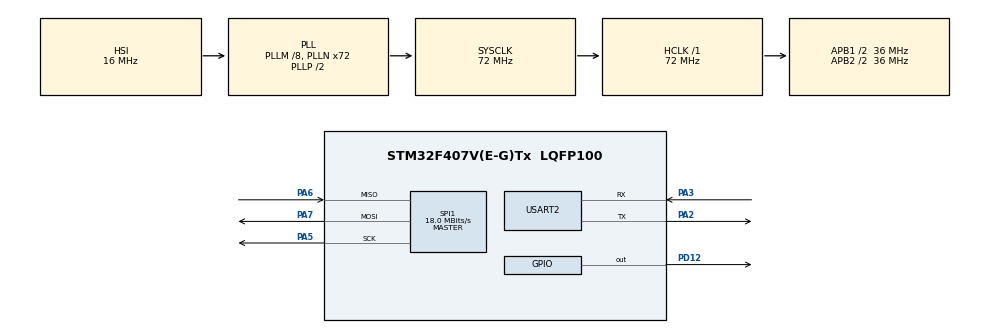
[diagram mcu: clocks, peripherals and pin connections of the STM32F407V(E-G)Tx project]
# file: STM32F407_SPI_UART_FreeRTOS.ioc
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FREERTOS.Tasks01=defaultTask,0,128,StartDefaultTask,Default,NULL
Mcu.Family=STM32F4
Mcu.Name=STM32F407V(E-G)Tx
Mcu.Package=LQFP100
NVIC.PriorityGroup=NVIC_PRIORITYGROUP_4
NVIC.TIM1_UP_TIM10_IRQn=true\:0\:0\:false\:false\:true\:false\:false
NVIC.TimeBase=TIM1_UP_TIM10_IRQn
NVIC.TimeBaseIP=TIM1
PA2.Mode=Asynchronous
PA2.Signal=USART2_TX
PA3.Mode=Asynchronous
PA3.Signal=USART2_RX
PA5.Mode=Full_Duplex_Master
PA5.Signal=SPI1_SCK
PA6.Mode=Full_Duplex_Master
PA6.Signal=SPI1_MISO
PA7.Mode=Full_Duplex_Master
PA7.Signal=SPI1_MOSI
PD12.Signal=GPIO_Output
PH0-OSC_IN.Mode=HSE-External-Oscillator
PH0-OSC_IN.Signal=RCC_OSC_IN
PH1-OSC_OUT.Mode=HSE-External-Oscillator
PH1-OSC_OUT.Signal=RCC_OSC_OUT
ProjectManager.HeapSize=0x200
ProjectManager.StackSize=0x400
ProjectManager.TargetToolchain=TrueSTUDIO
RCC.48MHZClocksFreq_Value=36000000
RCC.AHBFreq_Value=72000000
RCC.APB1CLKDivider=RCC_HCLK_DIV2
RCC.APB1Freq_Value=36000000
RCC.APB1TimFreq_Value=72000000
RCC.APB2CLKDivider=RCC_HCLK_DIV2
RCC.APB2Freq_Value=36000000
RCC.APB2TimFreq_Value=72000000
RCC.CortexFreq_Value=72000000
RCC.HCLKFreq_Value=72000000
RCC.HSE_VALUE=8000000
RCC.HSI_VALUE=16000000
RCC.LSE_VALUE=32768
RCC.PLLM=8
RCC.PLLN=72
RCC.SYSCLKFreq_VALUE=72000000
RCC.SYSCLKSource=RCC_SYSCLKSOURCE_PLLCLK
RCC.VCOOutputFreq_Value=144000000
SPI1.BaudRatePrescaler=SPI_BAUDRATEPRESCALER_2
SPI1.CalculateBaudRate=18.0 MBits/s
SPI1.Direction=SPI_DIRECTION_2LINES
SPI1.Mode=SPI_MODE_MASTER
SPI1.VirtualType=VM_MASTER
USART2.VirtualMode=VM_ASYNC
VP_FREERTOS_VS_ENABLE.Mode=Enabled
VP_SYS_VS_tim1.Mode=TIM1
board=STM32F407_SPI_UART_FreeRTOS

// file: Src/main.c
/**
  ******************************************************************************
  * File Name          : main.c
  * Description        : Main program body
  ******************************************************************************
  * This notice applies to any and all portions of this file
  * that are not between comment pairs USER CODE BEGIN and
  * USER CODE END. Other portions of this file, whether
  * inserted by the user or by software development tools
  * are owned by their respective copyright owners.
  *
  * Copyright (c) 2020 STMicroelectronics International N.V.
  * All rights reserved.
  *
  * Redistribution and use in source and binary forms, with or without
  * modification, are permitted, provided that the following conditions are met:
  *
  * 1. Redistribution of source code must retain the above copyright notice,
  *    this list of conditions and the following disclaimer.
  * 2. Redistributions in binary form must reproduce the above copyright notice,
  *    this list of conditions and the following disclaimer in the documentation
  *    and/or other materials provided with the distribution.
  * 3. Neither the name of STMicroelectronics nor the names of other
  *    contributors to this software may be used to endorse or promote products
  *    derived from this software without specific written permission.
  * 4. This software, including modifications and/or derivative works of this
  *    software, must execute solely and exclusively on microcontroller or
  *    microprocessor devices manufactured by or for STMicroelectronics.
  * 5. Redistribution and use of this software other than as permitted under
  *    this license is void and will automatically terminate your rights under
  *    this license.
  *
  * THIS SOFTWARE IS PROVIDED BY STMICROELECTRONICS AND CONTRIBUTORS "AS IS"
  * AND ANY EXPRESS, IMPLIED OR STATUTORY WARRANTIES, INCLUDING, BUT NOT
  * LIMITED TO, THE IMPLIED WARRANTIES OF MERCHANTABILITY, FITNESS FOR A
  * PARTICULAR PURPOSE AND NON-INFRINGEMENT OF THIRD PARTY INTELLECTUAL PROPERTY
  * RIGHTS ARE DISCLAIMED TO THE FULLEST EXTENT PERMITTED BY LAW. IN NO EVENT
  * SHALL STMICROELECTRONICS OR CONTRIBUTORS BE LIABLE FOR ANY DIRECT, INDIRECT,
  * INCIDENTAL, SPECIAL, EXEMPLARY, OR CONSEQUENTIAL DAMAGES (INCLUDING, BUT NOT
  * LIMITED TO, PROCUREMENT OF SUBSTITUTE GOODS OR SERVICES; LOSS OF USE, DATA,
  * OR PROFITS; OR BUSINESS INTERRUPTION) HOWEVER CAUSED AND ON ANY THEORY OF
  * LIABILITY, WHETHER IN CONTRACT, STRICT LIABILITY, OR TORT (INCLUDING
  * NEGLIGENCE OR OTHERWISE) ARISING IN ANY WAY OUT OF THE USE OF THIS SOFTWARE,
  * EVEN IF ADVISED OF THE POSSIBILITY OF SUCH DAMAGE.
  *
  ******************************************************************************
  */

#include "main.h"
#include "stm32f4xx_hal.h"
#include "cmsis_os.h"

SPI_HandleTypeDef hspi1;

UART_HandleTypeDef huart2;

osThreadId defaultTaskHandle;

/* USER CODE BEGIN PV */
/* Private variables ---------------------------------------------------------*/

/* USER CODE END PV */

void SystemClock_Config(void);
static void MX_GPIO_Init(void);
static void MX_USART2_UART_Init(void);
static void MX_SPI1_Init(void);
void StartDefaultTask(void const * argument);

/* USER CODE BEGIN PFP */
/* Private function prototypes -----------------------------------------------*/

/* USER CODE END PFP */

/* USER CODE BEGIN 0 */

void UART_task1()
{
	uint8_t pData[100];
	while(1)
	{
//		HAL_UART_Receive( &huart2, pData, sizeof(pData), 500);
		vTaskDelay(1);
	}
}

void SPI_task2()
{
	uint8_t pData[100];
	while(1)
	{
		HAL_SPI_Receive( &hspi1, pData, sizeof(pData), 500);
		HAL_UART_Transmit( &huart2, pData, sizeof(pData), 500);
		memset(pData,'\0', sizeof(pData));
		vTaskDelay(1);
	}
}

/* USER CODE END 0 */

int main(void)
{

  /* MCU Configuration----------------------------------------------------------*/

  /* Reset of all peripherals, Initializes the Flash interface and the Systick. */
  HAL_Init();

  /* Configure the system clock */
  SystemClock_Config();

  /* Initialize all configured peripherals */
  MX_GPIO_Init();
  MX_USART2_UART_Init();
  MX_SPI1_Init();

  /* Create the thread(s) */
  /* definition and creation of defaultTask */
  osThreadDef(defaultTask, StartDefaultTask, osPriorityNormal, 0, 128);
  defaultTaskHandle = osThreadCreate(osThread(defaultTask), NULL);

  /* USER CODE BEGIN RTOS_THREADS */
  /* add threads, ... */

  /* Add the main task into FreeRTOS task scheduler. */
  		xTaskCreate(UART_task1, "Main Task1", 512, NULL, 1, NULL);
  		xTaskCreate(SPI_task2, "Main Task2", 512, NULL, 0, NULL);

  		/* Start FreeRTOS task scheduler. */
  		vTaskStartScheduler();

  /* USER CODE END RTOS_THREADS */

  /* Start scheduler */
  osKernelStart();

  /* We should never get here as control is now taken by the scheduler */

  /* Infinite loop */
  while (1)
  {

  }

}

/** System Clock Configuration
*/
void SystemClock_Config(void)
{

  RCC_OscInitTypeDef RCC_OscInitStruct;
  RCC_ClkInitTypeDef RCC_ClkInitStruct;

    /**Configure the main internal regulator output voltage
    */
  __HAL_RCC_PWR_CLK_ENABLE();

  __HAL_PWR_VOLTAGESCALING_CONFIG(PWR_REGULATOR_VOLTAGE_SCALE1);

    /**Initializes the CPU, AHB and APB busses clocks
    */
  RCC_OscInitStruct.OscillatorType = RCC_OSCILLATORTYPE_HSI;
  RCC_OscInitStruct.HSIState = RCC_HSI_ON;
  RCC_OscInitStruct.HSICalibrationValue = 16;
  RCC_OscInitStruct.PLL.PLLState = RCC_PLL_ON;
  RCC_OscInitStruct.PLL.PLLSource = RCC_PLLSOURCE_HSI;
  RCC_OscInitStruct.PLL.PLLM = 8;
  RCC_OscInitStruct.PLL.PLLN = 72;
  RCC_OscInitStruct.PLL.PLLP = RCC_PLLP_DIV2;
  RCC_OscInitStruct.PLL.PLLQ = 4;
  if (HAL_RCC_OscConfig(&RCC_OscInitStruct) != HAL_OK)
  {
    _Error_Handler(__FILE__, __LINE__);
  }

    /**Initializes the CPU, AHB and APB busses clocks
    */
  RCC_ClkInitStruct.ClockType = RCC_CLOCKTYPE_HCLK|RCC_CLOCKTYPE_SYSCLK
                              |RCC_CLOCKTYPE_PCLK1|RCC_CLOCKTYPE_PCLK2;
  RCC_ClkInitStruct.SYSCLKSource = RCC_SYSCLKSOURCE_PLLCLK;
  RCC_ClkInitStruct.AHBCLKDivider = RCC_SYSCLK_DIV1;
  RCC_ClkInitStruct.APB1CLKDivider = RCC_HCLK_DIV2;
  RCC_ClkInitStruct.APB2CLKDivider = RCC_HCLK_DIV2;

  if (HAL_RCC_ClockConfig(&RCC_ClkInitStruct, FLASH_LATENCY_2) != HAL_OK)
  {
    _Error_Handler(__FILE__, __LINE__);
  }

    /**Configure the Systick interrupt time
    */
  HAL_SYSTICK_Config(HAL_RCC_GetHCLKFreq()/1000);

    /**Configure the Systick
    */
  HAL_SYSTICK_CLKSourceConfig(SYSTICK_CLKSOURCE_HCLK);

  /* SysTick_IRQn interrupt configuration */
  HAL_NVIC_SetPriority(SysTick_IRQn, 15, 0);
}

/* SPI1 init function */
static void MX_SPI1_Init(void)
{

  /* SPI1 parameter configuration*/
  hspi1.Instance = SPI1;
  hspi1.Init.Mode = SPI_MODE_MASTER;
  hspi1.Init.Direction = SPI_DIRECTION_2LINES;
  hspi1.Init.DataSize = SPI_DATASIZE_8BIT;
  hspi1.Init.CLKPolarity = SPI_POLARITY_LOW;
  hspi1.Init.CLKPhase = SPI_PHASE_1EDGE;
  hspi1.Init.NSS = SPI_NSS_SOFT;
  hspi1.Init.BaudRatePrescaler = SPI_BAUDRATEPRESCALER_2;
  hspi1.Init.FirstBit = SPI_FIRSTBIT_MSB;
  hspi1.Init.TIMode = SPI_TIMODE_DISABLE;
  hspi1.Init.CRCCalculation = SPI_CRCCALCULATION_DISABLE;
  hspi1.Init.CRCPolynomial = 10;
  if (HAL_SPI_Init(&hspi1) != HAL_OK)
  {
    _Error_Handler(__FILE__, __LINE__);
  }

}

/* USART2 init function */
static void MX_USART2_UART_Init(void)
{

  huart2.Instance = USART2;
  huart2.Init.BaudRate = 115200;
  huart2.Init.WordLength = UART_WORDLENGTH_8B;
  huart2.Init.StopBits = UART_STOPBITS_1;
  huart2.Init.Parity = UART_PARITY_NONE;
  huart2.Init.Mode = UART_MODE_TX_RX;
  huart2.Init.HwFlowCtl = UART_HWCONTROL_NONE;
  huart2.Init.OverSampling = UART_OVERSAMPLING_16;
  if (HAL_UART_Init(&huart2) != HAL_OK)
  {
    _Error_Handler(__FILE__, __LINE__);
  }

}

/** Configure pins as
        * Analog
        * Input
        * Output
        * EVENT_OUT
        * EXTI
*/
static void MX_GPIO_Init(void)
{

  GPIO_InitTypeDef GPIO_InitStruct;

  /* GPIO Ports Clock Enable */
  __HAL_RCC_GPIOH_CLK_ENABLE();
  __HAL_RCC_GPIOA_CLK_ENABLE();
  __HAL_RCC_GPIOD_CLK_ENABLE();

  /*Configure GPIO pin Output Level */
  HAL_GPIO_WritePin(GPIOD, GPIO_PIN_12, GPIO_PIN_RESET);

  /*Configure GPIO pin : PD12 */
  GPIO_InitStruct.Pin = GPIO_PIN_12;
  GPIO_InitStruct.Mode = GPIO_MODE_OUTPUT_PP;
  GPIO_InitStruct.Pull = GPIO_NOPULL;
  GPIO_InitStruct.Speed = GPIO_SPEED_FREQ_LOW;
  HAL_GPIO_Init(GPIOD, &GPIO_InitStruct);

}

/* StartDefaultTask function */
void StartDefaultTask(void const * argument)
{

  for(;;)
  {
    osDelay(1);
  }
}

void HAL_TIM_PeriodElapsedCallback(TIM_HandleTypeDef *htim)
{
  if (htim->Instance == TIM1) {
    HAL_IncTick();
  }
}

void _Error_Handler(char * file, int line)
{
  while(1)
  {
  }
}

/************************ (C) COPYRIGHT STMicroelectronics *****END OF FILE****/
